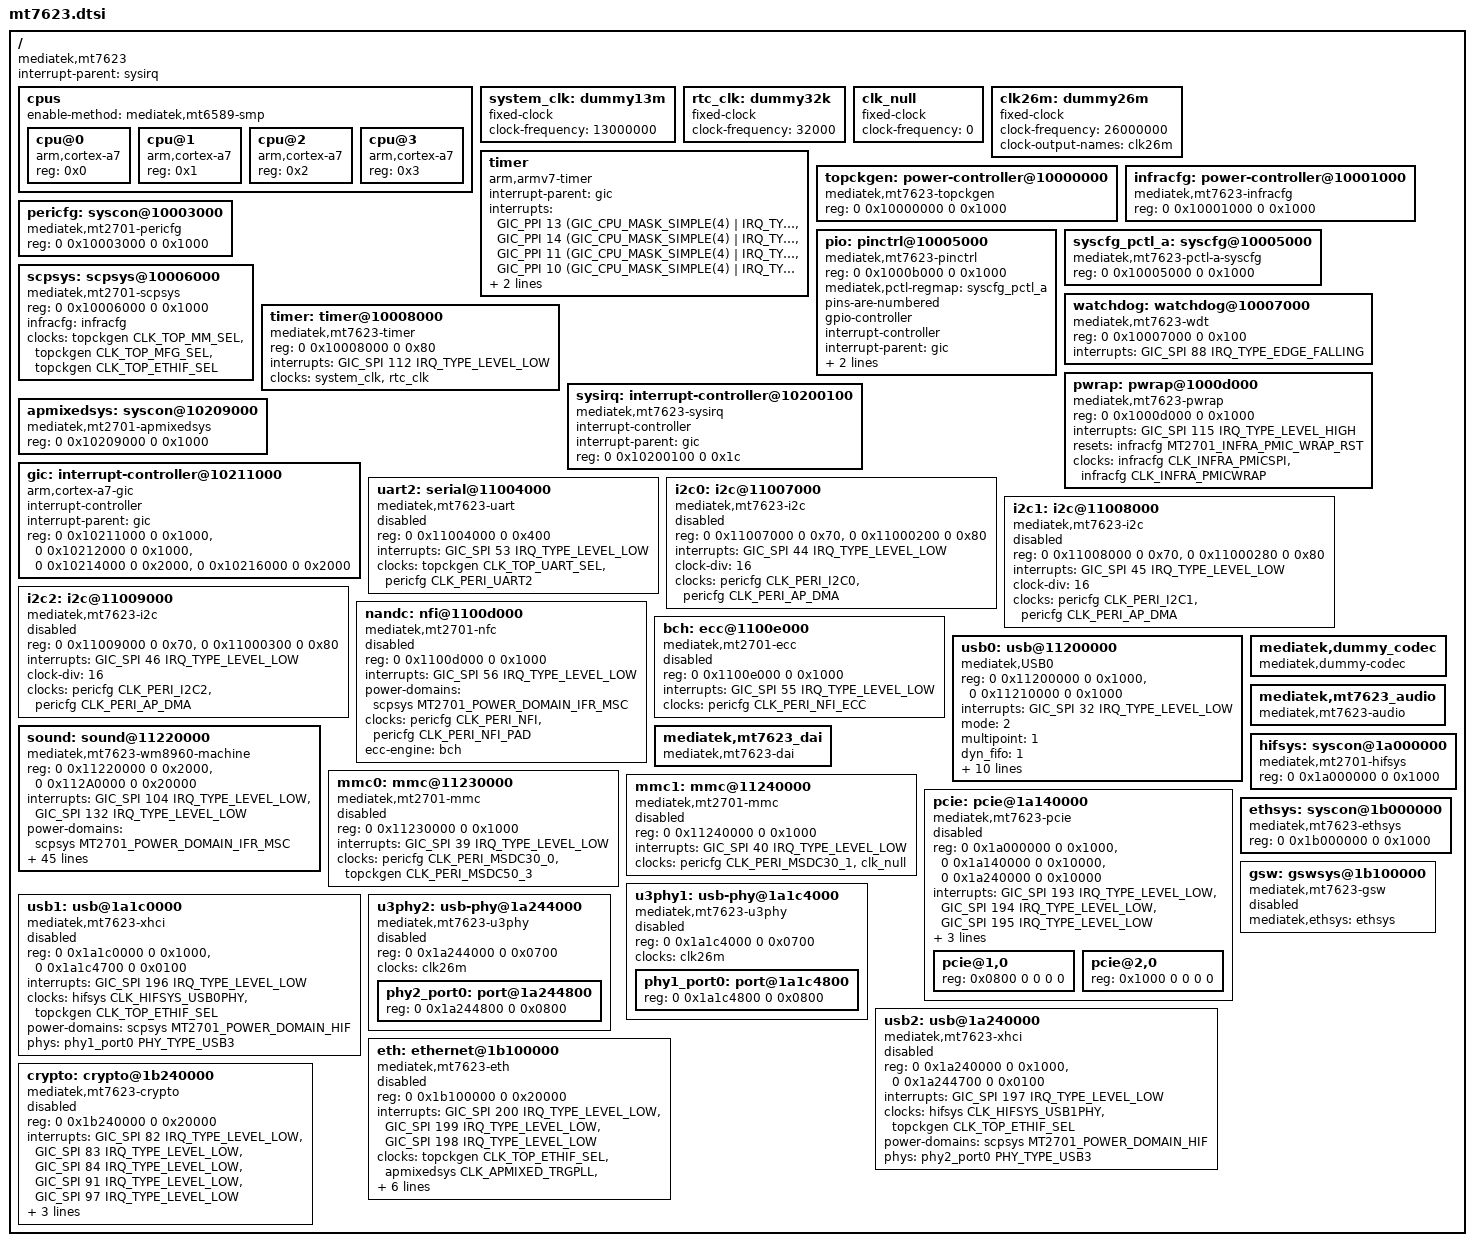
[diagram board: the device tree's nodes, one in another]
/*
 * Copyright (c) 2016 MediaTek Inc.
 * Author: Sean Wang <sean.wang@mediatek.com>
 *
 * This program is free software; you can redistribute it and/or modify
 * it under the terms of the GNU General Public License version 2 as
 * published by the Free Software Foundation.
 *
 * This program is distributed in the hope that it will be useful,
 * but WITHOUT ANY WARRANTY; without even the implied warranty of
 * MERCHANTABILITY or FITNESS FOR A PARTICULAR PURPOSE.  See the
 * GNU General Public License for more details.
 */

#include <dt-bindings/interrupt-controller/irq.h>
#include <dt-bindings/interrupt-controller/arm-gic.h>
#include <dt-bindings/clock/mt2701-clk.h>
#include <dt-bindings/power/mt2701-power.h>
#include <dt-bindings/phy/phy.h>
#include <dt-bindings/reset/mt2701-resets.h>
#include <dt-bindings/pinctrl/mt7623-pinfunc.h>
#include "skeleton64.dtsi"

/ {
	compatible = "mediatek,mt7623";
	interrupt-parent = <&sysirq>;

	cpus {
		#address-cells = <1>;
		#size-cells = <0>;
		enable-method = "mediatek,mt6589-smp";

		cpu@0 {
			device_type = "cpu";
			compatible = "arm,cortex-a7";
			reg = <0x0>;
		};
		cpu@1 {
			device_type = "cpu";
			compatible = "arm,cortex-a7";
			reg = <0x1>;
		};
		cpu@2 {
			device_type = "cpu";
			compatible = "arm,cortex-a7";
			reg = <0x2>;
		};
		cpu@3 {
			device_type = "cpu";
			compatible = "arm,cortex-a7";
			reg = <0x3>;
		};
	};

	system_clk: dummy13m {
		compatible = "fixed-clock";
		clock-frequency = <13000000>;
		#clock-cells = <0>;
	};

	rtc_clk: dummy32k {
		compatible = "fixed-clock";
		clock-frequency = <32000>;
		#clock-cells = <0>;
	};

	clk_null: clk_null {
		compatible = "fixed-clock";
		#clock-cells = <0>;
		clock-frequency = <0>;
	};

	clk26m: dummy26m {
		compatible = "fixed-clock";
		clock-frequency = <26000000>;
		#clock-cells = <0>;
		clock-output-names = "clk26m";
	};

	timer {
		compatible = "arm,armv7-timer";
		interrupt-parent = <&gic>;
		interrupts = <GIC_PPI 13 (GIC_CPU_MASK_SIMPLE(4) | IRQ_TYPE_LEVEL_HIGH)>,
			     <GIC_PPI 14 (GIC_CPU_MASK_SIMPLE(4) | IRQ_TYPE_LEVEL_HIGH)>,
			     <GIC_PPI 11 (GIC_CPU_MASK_SIMPLE(4) | IRQ_TYPE_LEVEL_HIGH)>,
			     <GIC_PPI 10 (GIC_CPU_MASK_SIMPLE(4) | IRQ_TYPE_LEVEL_HIGH)>;
		clock-frequency = <13000000>;
		arm,cpu-registers-not-fw-configured;
	};

	topckgen: power-controller@10000000 {
		compatible = "mediatek,mt7623-topckgen",
			     "mediatek,mt2701-topckgen",
			     "syscon";
		reg = <0 0x10000000 0 0x1000>;
		#clock-cells = <1>;
	};

	infracfg: power-controller@10001000 {
		compatible = "mediatek,mt7623-infracfg",
			     "mediatek,mt2701-infracfg",
			     "syscon";
		reg = <0 0x10001000 0 0x1000>;
		#clock-cells = <1>;
		#reset-cells = <1>;
	};

	pericfg: syscon@10003000 {
		compatible = "mediatek,mt2701-pericfg", "syscon";
		reg = <0 0x10003000 0 0x1000>;
		#clock-cells = <1>;
		#reset-cells = <1>;
	};

	pio: pinctrl@10005000 {
		compatible = "mediatek,mt7623-pinctrl",
			     "mediatek,mt2701-pinctrl";
		reg = <0 0x1000b000 0 0x1000>;
		mediatek,pctl-regmap = <&syscfg_pctl_a>;
		pins-are-numbered;
		gpio-controller;
		#gpio-cells = <2>;
		interrupt-controller;
		interrupt-parent = <&gic>;
		#interrupt-cells = <2>;
		interrupts = <GIC_SPI 113 IRQ_TYPE_LEVEL_HIGH>,
			     <GIC_SPI 114 IRQ_TYPE_LEVEL_HIGH>;
	};

	syscfg_pctl_a: syscfg@10005000 {
		compatible = "mediatek,mt7623-pctl-a-syscfg", "syscon";
		reg = <0 0x10005000 0 0x1000>;
	};

	scpsys: scpsys@10006000 {
		compatible = "mediatek,mt2701-scpsys", "syscon";
		#power-domain-cells = <1>;
		reg = <0 0x10006000 0 0x1000>;
		infracfg = <&infracfg>;
		clocks = <&topckgen CLK_TOP_MM_SEL>,
			 <&topckgen CLK_TOP_MFG_SEL>,
			 <&topckgen CLK_TOP_ETHIF_SEL>;
		clock-names = "mm", "mfg", "ethif";
	};

	watchdog: watchdog@10007000 {
		compatible = "mediatek,mt7623-wdt",
			     "mediatek,mt6589-wdt";
		reg = <0 0x10007000 0 0x100>;
		interrupts = <GIC_SPI 88 IRQ_TYPE_EDGE_FALLING>;
		#reset-cells = <1>;
	};

	timer: timer@10008000 {
		compatible = "mediatek,mt7623-timer",
			     "mediatek,mt6577-timer";
		reg = <0 0x10008000 0 0x80>;
		interrupts = <GIC_SPI 112 IRQ_TYPE_LEVEL_LOW>;
		clocks = <&system_clk>, <&rtc_clk>;
		clock-names = "system-clk", "rtc-clk";
	};

	pwrap: pwrap@1000d000 {
		compatible = "mediatek,mt7623-pwrap",
			     "mediatek,mt2701-pwrap";
		reg = <0 0x1000d000 0 0x1000>;
		reg-names = "pwrap";
		interrupts = <GIC_SPI 115 IRQ_TYPE_LEVEL_HIGH>;
		resets = <&infracfg MT2701_INFRA_PMIC_WRAP_RST>;
		reset-names = "pwrap";
		clocks = <&infracfg CLK_INFRA_PMICSPI>,
			 <&infracfg CLK_INFRA_PMICWRAP>;
		clock-names = "spi", "wrap";
	};

	sysirq: interrupt-controller@10200100 {
		compatible = "mediatek,mt7623-sysirq",
			     "mediatek,mt6577-sysirq";
		interrupt-controller;
		#interrupt-cells = <3>;
		interrupt-parent = <&gic>;
		reg = <0 0x10200100 0 0x1c>;
	};

	apmixedsys: syscon@10209000 {
		compatible = "mediatek,mt2701-apmixedsys", "syscon";
		reg = <0 0x10209000 0 0x1000>;
		#clock-cells = <1>;
	};
	gic: interrupt-controller@10211000 {
		compatible = "arm,cortex-a7-gic";
		interrupt-controller;
		#interrupt-cells = <3>;
		interrupt-parent = <&gic>;
		reg = <0 0x10211000 0 0x1000>,
		      <0 0x10212000 0 0x1000>,
		      <0 0x10214000 0 0x2000>,
		      <0 0x10216000 0 0x2000>;
	};

	uart2: serial@11004000 {
		compatible = "mediatek,mt7623-uart",
			     "mediatek,mt6577-uart";
		reg = <0 0x11004000 0 0x400>;
		interrupts = <GIC_SPI 53 IRQ_TYPE_LEVEL_LOW>;
		clocks = <&topckgen CLK_TOP_UART_SEL>, <&pericfg CLK_PERI_UART2>;
		clock-names = "baud", "bus";
		status = "disabled";
	};

	i2c0: i2c@11007000 {
		compatible = "mediatek,mt7623-i2c",
			     "mediatek,mt6577-i2c";
		reg = <0 0x11007000 0 0x70>,
		      <0 0x11000200 0 0x80>;
		interrupts = <GIC_SPI 44 IRQ_TYPE_LEVEL_LOW>;
		clock-div = <16>;
		clocks = <&pericfg CLK_PERI_I2C0>, <&pericfg CLK_PERI_AP_DMA>;
		clock-names = "main", "dma";
		#address-cells = <1>;
		#size-cells = <0>;
		status = "disabled";
	};

	i2c1: i2c@11008000 {
		compatible = "mediatek,mt7623-i2c",
			     "mediatek,mt6577-i2c";
		reg = <0 0x11008000 0 0x70>,
		      <0 0x11000280 0 0x80>;
		interrupts = <GIC_SPI 45 IRQ_TYPE_LEVEL_LOW>;
		clock-div = <16>;
		clocks = <&pericfg CLK_PERI_I2C1>, <&pericfg CLK_PERI_AP_DMA>;
		clock-names = "main", "dma";
		#address-cells = <1>;
		#size-cells = <0>;
		status = "disabled";
	};

	i2c2: i2c@11009000 {
		compatible = "mediatek,mt7623-i2c",
			     "mediatek,mt6577-i2c";
		reg = <0 0x11009000 0 0x70>,
		      <0 0x11000300 0 0x80>;
		interrupts = <GIC_SPI 46 IRQ_TYPE_LEVEL_LOW>;
		clock-div = <16>;
		clocks = <&pericfg CLK_PERI_I2C2>, <&pericfg CLK_PERI_AP_DMA>;
		clock-names = "main", "dma";
		#address-cells = <1>;
		#size-cells = <0>;
		status = "disabled";
	};

	nandc: nfi@1100d000 {
		compatible = "mediatek,mt2701-nfc";
		reg = <0 0x1100d000 0 0x1000>;
		interrupts = <GIC_SPI 56 IRQ_TYPE_LEVEL_LOW>;
		power-domains = <&scpsys MT2701_POWER_DOMAIN_IFR_MSC>;
		clocks = <&pericfg CLK_PERI_NFI>,<&pericfg CLK_PERI_NFI_PAD>;
		clock-names = "nfi_clk", "pad_clk";
		status = "disabled";
		ecc-engine = <&bch>;
		#address-cells = <1>;
		#size-cells = <0>;
	};

	bch: ecc@1100e000 {
		compatible = "mediatek,mt2701-ecc";
		reg = <0 0x1100e000 0 0x1000>;
		interrupts = <GIC_SPI 55 IRQ_TYPE_LEVEL_LOW>;
		clocks = <&pericfg CLK_PERI_NFI_ECC>;
		clock-names = "nfiecc_clk";
		status = "disabled";
	};

	usb0: usb@11200000 {
		compatible = "mediatek,USB0";
		reg = <0 0x11200000 0 0x1000>,
		      <0 0x11210000 0 0x1000>;
		interrupts = <GIC_SPI 32 IRQ_TYPE_LEVEL_LOW>;
		mode = <2>;
		multipoint = <1>;
		dyn_fifo = <1>;
		soft_con = <1>;
		dma = <1>;
		num_eps = <16>;
		dma_channels = <8>;
		clocks = <&pericfg CLK_PERI_USB0>,
			 <&pericfg CLK_PERI_USB0_MCU>,
			 <&pericfg CLK_PERI_USB_SLV>;
		clock-names = "usb0_main","usb0_mcu","usb_slv";
		power-domains = <&scpsys MT2701_POWER_DOMAIN_IFR_MSC>;
		usb-power-supply = <&mt6323_vusb_reg>;
	};

	sound:sound@11220000 {
		compatible = "mediatek,mt7623-wm8960-machine";
		#address-cells = <2>;
		#size-cells = <2>;
		 reg = <0 0x11220000 0 0x2000>,
		       <0 0x112A0000 0 0x20000>;
		interrupts = <GIC_SPI 104 IRQ_TYPE_LEVEL_LOW>,
			     <GIC_SPI 132 IRQ_TYPE_LEVEL_LOW>;
		power-domains = <&scpsys MT2701_POWER_DOMAIN_IFR_MSC>;
		clocks = <&infracfg CLK_INFRA_AUDIO>,
			 <&topckgen CLK_TOP_AUD_MUX1_SEL>,
			 <&topckgen CLK_TOP_AUD_MUX2_SEL>,
			 <&topckgen CLK_TOP_AUD_MUX1_DIV>,
			 <&topckgen CLK_TOP_AUD_MUX2_DIV>,
			 <&topckgen CLK_TOP_AUD_48K_TIMING>,
			 <&topckgen CLK_TOP_AUD_44K_TIMING>,
			 <&topckgen CLK_TOP_AUDPLL_MUX_SEL>,
			 <&topckgen CLK_TOP_APLL_SEL>,
			 <&topckgen CLK_TOP_AUD1PLL_98M>,
			 <&topckgen CLK_TOP_AUD2PLL_90M>,
			 <&topckgen CLK_TOP_HADDS2PLL_98M>,
			 <&topckgen CLK_TOP_HADDS2PLL_294M>,
			 <&topckgen CLK_TOP_AUDPLL>,
			 <&topckgen CLK_TOP_AUDPLL_D4>,
			 <&topckgen CLK_TOP_AUDPLL_D8>,
			 <&topckgen CLK_TOP_AUDPLL_D16>,
			 <&topckgen CLK_TOP_AUDPLL_D24>,
			 <&topckgen CLK_TOP_AUDINTBUS_SEL>,
			 <&clk26m>,
			 <&topckgen CLK_TOP_SYSPLL1_D4>,
			 <&topckgen CLK_TOP_AUD_K1_SRC_SEL>,
			 <&topckgen CLK_TOP_AUD_K2_SRC_SEL>,
			 <&topckgen CLK_TOP_AUD_K3_SRC_SEL>,
			 <&topckgen CLK_TOP_AUD_K4_SRC_SEL>,
			 <&topckgen CLK_TOP_AUD_K5_SRC_SEL>,
			 <&topckgen CLK_TOP_AUD_K6_SRC_SEL>,
			 <&topckgen CLK_TOP_AUD_K1_SRC_DIV>,
			 <&topckgen CLK_TOP_AUD_K2_SRC_DIV>,
			 <&topckgen CLK_TOP_AUD_K3_SRC_DIV>,
			 <&topckgen CLK_TOP_AUD_K4_SRC_DIV>,
			 <&topckgen CLK_TOP_AUD_K5_SRC_DIV>,
			 <&topckgen CLK_TOP_AUD_K6_SRC_DIV>,
			 <&topckgen CLK_TOP_AUD_I2S1_MCLK>,
			 <&topckgen CLK_TOP_AUD_I2S2_MCLK>,
			 <&topckgen CLK_TOP_AUD_I2S3_MCLK>,
			 <&topckgen CLK_TOP_AUD_I2S4_MCLK>,
			 <&topckgen CLK_TOP_AUD_I2S5_MCLK>,
			 <&topckgen CLK_TOP_AUD_I2S6_MCLK>,
			 <&topckgen CLK_TOP_ASM_M_SEL>,
			 <&topckgen CLK_TOP_ASM_H_SEL>,
			 <&topckgen CLK_TOP_UNIVPLL2_D4>,
			 <&topckgen CLK_TOP_UNIVPLL2_D2>,
			 <&topckgen CLK_TOP_SYSPLL_D5>,
			 <&topckgen CLK_TOP_UNIVPLL_D2>,
			 <&topckgen CLK_TOP_INTDIR_SEL>;

		clock-names = "infra_sys_audio_clk",
			      "top_audio_mux1_sel",
			      "top_audio_mux2_sel",
			      "top_audio_mux1_div",
			      "top_audio_mux2_div",
			      "top_audio_48k_timing",
			      "top_audio_44k_timing",
			      "top_audpll_mux_sel",
			      "top_apll_sel",
			      "top_aud1_pll_98M",
			      "top_aud2_pll_90M",
			      "top_hadds2_pll_98M",
			      "top_hadds2_pll_294M",
			      "top_audpll",
			      "top_audpll_d4",
			      "top_audpll_d8",
			      "top_audpll_d16",
			      "top_audpll_d24",
			      "top_audintbus_sel",
			      "clk_26m",
			      "top_syspll1_d4",
			      "top_aud_k1_src_sel",
			      "top_aud_k2_src_sel",
			      "top_aud_k3_src_sel",
			      "top_aud_k4_src_sel",
			      "top_aud_k5_src_sel",
			      "top_aud_k6_src_sel",
			      "top_aud_k1_src_div",
			      "top_aud_k2_src_div",
			      "top_aud_k3_src_div",
			      "top_aud_k4_src_div",
			      "top_aud_k5_src_div",
			      "top_aud_k6_src_div",
			      "top_aud_i2s1_mclk",
			      "top_aud_i2s2_mclk",
			      "top_aud_i2s3_mclk",
			      "top_aud_i2s4_mclk",
			      "top_aud_i2s5_mclk",
			      "top_aud_i2s6_mclk",
			      "top_asm_m_sel",
			      "top_asm_h_sel",
			      "top_univpll2_d4",
			      "top_univpll2_d2",
			      "top_syspll_d5",
			      "top_univpll_d2",
			      "top_intdir_sel";
	};

	mediatek,dummy_codec {
		compatible = "mediatek,dummy-codec";
	};

	mediatek,mt7623_audio {
		compatible = "mediatek,mt7623-audio", "mediatek,mt8521p-audio";
	};

	mediatek,mt7623_dai {
		compatible = "mediatek,mt7623-dai", "mediatek,mt8521p-dai";
	};

	mmc0: mmc@11230000 {
		compatible = "mediatek,mt2701-mmc";
		reg = <0 0x11230000 0 0x1000>;
		interrupts = <GIC_SPI 39 IRQ_TYPE_LEVEL_LOW>;
		clocks = <&pericfg CLK_PERI_MSDC30_0>,
			 <&topckgen CLK_PERI_MSDC50_3>;
		clock-names = "source", "hclk";
		status = "disabled";
	};

	mmc1: mmc@11240000 {
		compatible = "mediatek,mt2701-mmc";
		reg = <0 0x11240000 0 0x1000>;
		interrupts = <GIC_SPI 40 IRQ_TYPE_LEVEL_LOW>;
		clocks = <&pericfg CLK_PERI_MSDC30_1>,
			 <&clk_null>;
		clock-names = "source", "hclk";
		status = "disabled";
	};

	hifsys: syscon@1a000000 {
		compatible = "mediatek,mt2701-hifsys", "syscon";
		reg = <0 0x1a000000 0 0x1000>;
		#clock-cells = <1>;
	};

	pcie: pcie@1a140000 {
		compatible = "mediatek,mt7623-pcie";
		reg = <0 0x1a000000 0 0x1000>,  /* HIF SYSCTL registers */
		      <0 0x1a140000 0 0x10000>, /* PCI-Express registers */
		      <0 0x1a240000 0 0x10000>; /* USB registers  */
		interrupts = <GIC_SPI 193 IRQ_TYPE_LEVEL_LOW>,
			     <GIC_SPI 194 IRQ_TYPE_LEVEL_LOW>,
			     <GIC_SPI 195 IRQ_TYPE_LEVEL_LOW>;
		clocks = <&topckgen CLK_TOP_ETHIF_SEL>;
		clock-names = "pcie";
		power-domains = <&scpsys MT2701_POWER_DOMAIN_HIF>;
		status = "disabled";

		bus-range = <0x00 0xff>;
		#address-cells = <3>;
		#size-cells = <2>;

		ranges = <0x81000000 0 0x1a160000 0 0x1a160000 0 0x00010000 /* io space */
			  0x83000000 0 0x60000000 0 0x60000000 0 0x10000000>; /* pci memory */

		pcie@1,0 {
			device_type = "pci";
			reg = <0x0800 0 0 0 0>;

			#address-cells = <3>;
			#size-cells = <2>;
			ranges;
		};

		pcie@2,0{
			device_type = "pci";
			reg = <0x1000 0 0 0 0>;

			#address-cells = <3>;
			#size-cells = <2>;
			ranges;
		};
	};

	usb1: usb@1a1c0000 {
		compatible = "mediatek,mt7623-xhci", "mediatek,mt2701-xhci";
		reg = <0 0x1a1c0000 0 0x1000>,
		      <0 0x1a1c4700 0 0x0100>;
		reg-names = "mac", "ippc";
		interrupts = <GIC_SPI 196 IRQ_TYPE_LEVEL_LOW>;
		clocks = <&hifsys CLK_HIFSYS_USB0PHY>,
			 <&topckgen CLK_TOP_ETHIF_SEL>;
		clock-names = "sys_ck", "free_ck";
		power-domains = <&scpsys MT2701_POWER_DOMAIN_HIF>;
		phys = <&phy1_port0 PHY_TYPE_USB3>;
		status = "disabled";
	};

	u3phy1: usb-phy@1a1c4000 {
		compatible = "mediatek,mt7623-u3phy", "mediatek,mt2701-u3phy";
		reg = <0 0x1a1c4000 0 0x0700>;
		clocks = <&clk26m>;
		clock-names = "u3phya_ref";
		#address-cells = <2>;
		#size-cells = <2>;
		ranges;
		status = "disabled";

		phy1_port0: port@1a1c4800 {
			reg = <0 0x1a1c4800 0 0x0800>;
			#phy-cells = <1>;
			status = "okay";
		};
	};

	usb2: usb@1a240000 {
		compatible = "mediatek,mt7623-xhci", "mediatek,mt2701-xhci";
		reg = <0 0x1a240000 0 0x1000>,
		      <0 0x1a244700 0 0x0100>;
		reg-names = "mac", "ippc";
		interrupts = <GIC_SPI 197 IRQ_TYPE_LEVEL_LOW>;
		clocks = <&hifsys CLK_HIFSYS_USB1PHY>,
			 <&topckgen CLK_TOP_ETHIF_SEL>;
		clock-names = "sys_ck", "free_ck";
		power-domains = <&scpsys MT2701_POWER_DOMAIN_HIF>;
		phys = <&phy2_port0 PHY_TYPE_USB3>;
		status = "disabled";
	};

	u3phy2: usb-phy@1a244000 {
		compatible = "mediatek,mt7623-u3phy", "mediatek,mt2701-u3phy";
		reg = <0 0x1a244000 0 0x0700>;
		clocks = <&clk26m>;
		clock-names = "u3phya_ref";
		#address-cells = <2>;
		#size-cells = <2>;
		ranges;
		status = "disabled";

		phy2_port0: port@1a244800 {
			reg = <0 0x1a244800 0 0x0800>;
			#phy-cells = <1>;
			status = "okay";
		};
	};

	ethsys: syscon@1b000000 {
		#address-cells = <1>;
		#size-cells = <1>;
		compatible = "mediatek,mt7623-ethsys",
			     "mediatek,mt2701-ethsys",
			     "syscon";
		reg = <0 0x1b000000 0 0x1000>;
		#clock-cells = <1>;
	};

	eth: ethernet@1b100000 {
		compatible = "mediatek,mt7623-eth";
		reg = <0 0x1b100000 0 0x20000>;
		interrupts = <GIC_SPI 200 IRQ_TYPE_LEVEL_LOW>,
			     <GIC_SPI 199 IRQ_TYPE_LEVEL_LOW>,
			     <GIC_SPI 198 IRQ_TYPE_LEVEL_LOW>;
		clocks = <&topckgen CLK_TOP_ETHIF_SEL>,
			 <&apmixedsys CLK_APMIXED_TRGPLL>,
			 <&ethsys CLK_ETHSYS_ESW>,
			 <&ethsys CLK_ETHSYS_GP2>,
			 <&ethsys CLK_ETHSYS_GP1>;
		clock-names = "ethif", "trgpll", "esw", "gp2", "gp1";
		power-domains = <&scpsys MT2701_POWER_DOMAIN_ETH>;
		resets = <&watchdog MT2701_TOPRGU_ETHDMA_RST>;
		reset-names = "eth";
		mediatek,ethsys = <&ethsys>;
		mediatek,switch = <&gsw>;
		#reset-cells = <1>;
		#address-cells = <1>;
		#size-cells = <0>;
		status = "disabled";
	};

	gsw: gswsys@1b100000 {
		compatible = "mediatek,mt7623-gsw",
			     "mediatek,mt2701-gsw";
		mediatek,ethsys = <&ethsys>;
		status = "disabled";
	};

	crypto: crypto@1b240000 {
		compatible = "mediatek,mt7623-crypto";
		reg = <0 0x1b240000 0 0x20000>;
		interrupts = <GIC_SPI 82 IRQ_TYPE_LEVEL_LOW>,
			     <GIC_SPI 83 IRQ_TYPE_LEVEL_LOW>,
			     <GIC_SPI 84 IRQ_TYPE_LEVEL_LOW>,
			     <GIC_SPI 91 IRQ_TYPE_LEVEL_LOW>,
			     <GIC_SPI 97 IRQ_TYPE_LEVEL_LOW>;
		clocks = <&topckgen CLK_TOP_ETHIF_SEL>,
			 <&ethsys CLK_ETHSYS_CRYPTO>;
		clock-names = "ethif","cryp";
		power-domains = <&scpsys MT2701_POWER_DOMAIN_ETH>;
		status = "disabled";
	};
};
